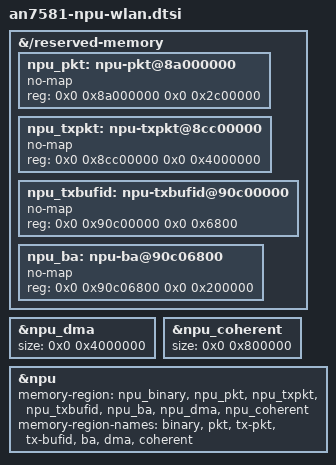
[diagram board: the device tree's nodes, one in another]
// SPDX-License-Identifier: (GPL-2.0-only OR BSD-2-Clause)

/*
 * Memory regions used by the NPU Wi-Fi packet offloading only. Boards that
 * do not run an Airoha-offloaded Wi-Fi chip must not reserve them: the NPU
 * uses the base firmware and DMA pools without these WLAN reservations.
 */

&{/reserved-memory} {
	#address-cells = <2>;
	#size-cells = <2>;
	ranges;

	npu_pkt: npu-pkt@8a000000 {
		no-map;
		reg = <0x0 0x8a000000 0x0 0x2c00000>;
	};

	npu_txpkt: npu-txpkt@8cc00000 {
		no-map;
		reg = <0x0 0x8cc00000 0x0 0x4000000>;
	};

	npu_txbufid: npu-txbufid@90c00000 {
		no-map;
		reg = <0x0 0x90c00000 0x0 0x6800>;
	};

	npu_ba: npu-ba@90c06800 {
		no-map;
		reg = <0x0 0x90c06800 0x0 0x200000>;
	};
};

&npu_dma {
	/* Streaming packet mappings share this pool across mt76 RX/TX queues. */
	size = <0x0 0x4000000>;
};

&npu_coherent {
	/* Includes the MT7992's contiguous 512 KiB descriptor allocations. */
	size = <0x0 0x800000>;
};

&npu {
	memory-region = <&npu_binary>, <&npu_pkt>, <&npu_txpkt>,
			<&npu_txbufid>, <&npu_ba>, <&npu_dma>, <&npu_coherent>;
	memory-region-names = "binary", "pkt", "tx-pkt",
			      "tx-bufid", "ba", "dma", "coherent";
};
